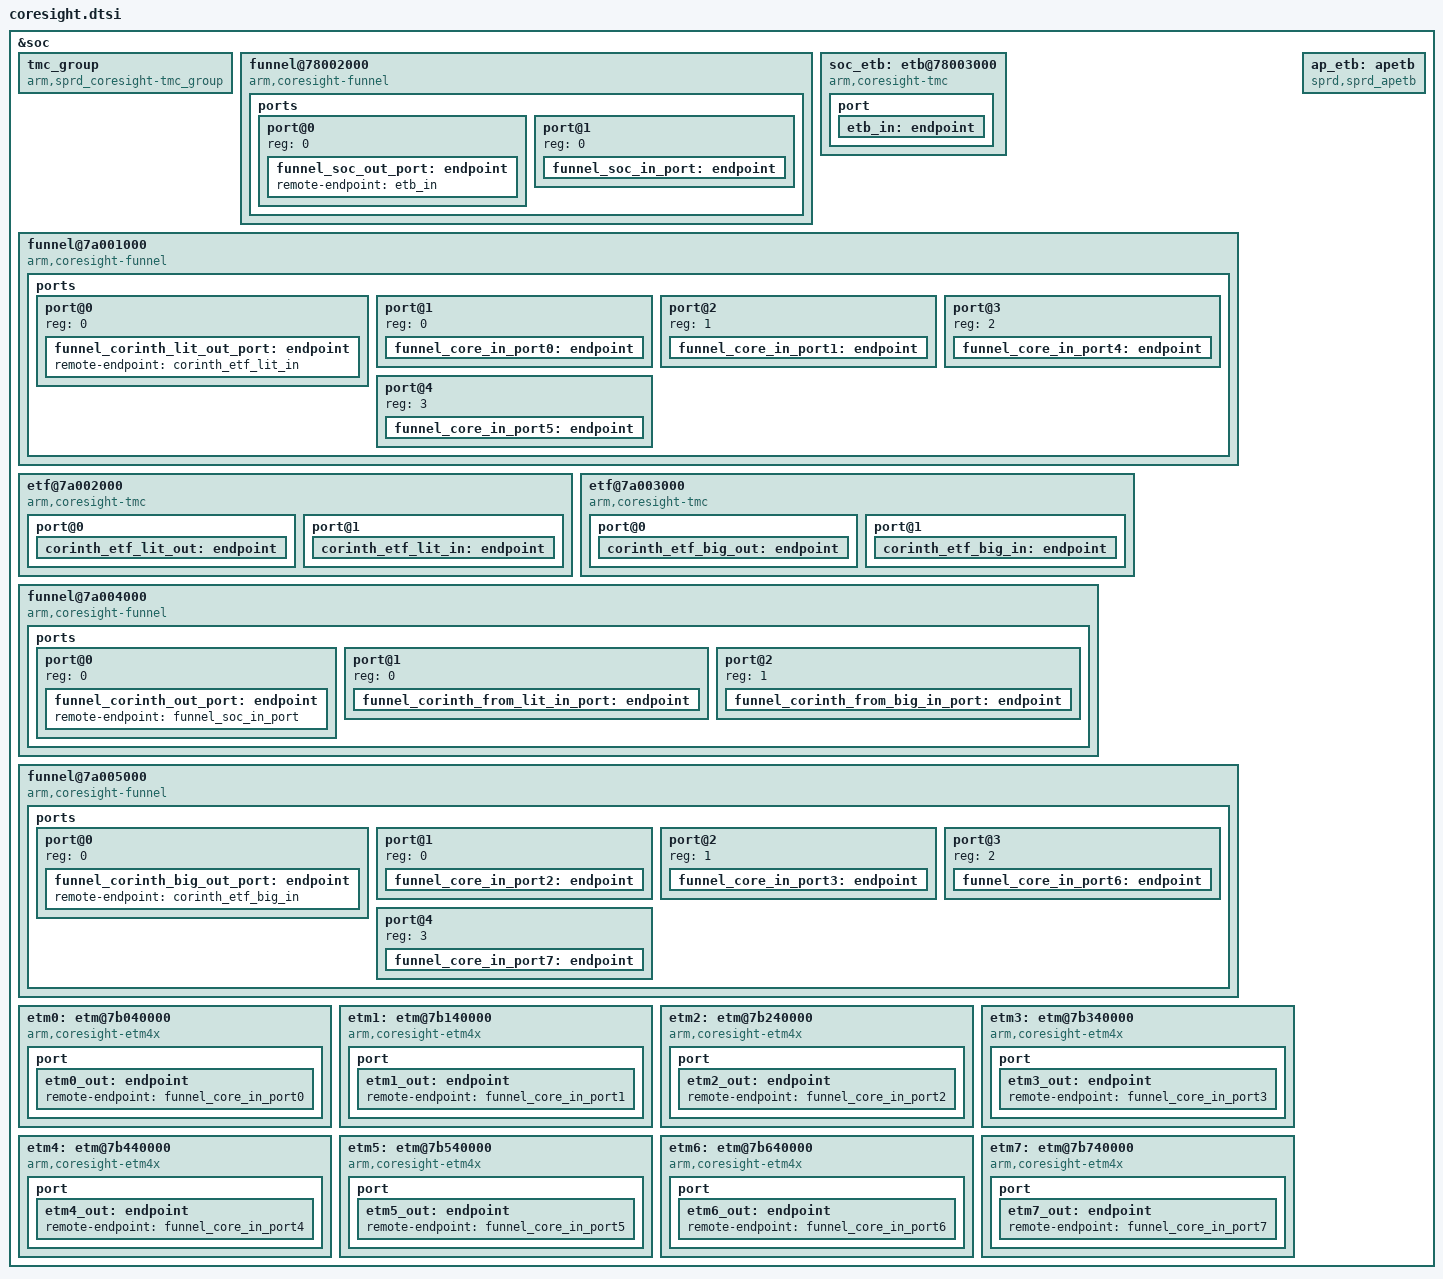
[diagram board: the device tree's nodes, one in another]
// SPDX-License-Identifier: (Licenseref-Unisoc-General-1.0 OR GPL-2.0-only)
/*
 * coresight.dtsi - Unisoc platform device
 *
 * Copyright 2022 Unisoc(Shanghai) Technologies Co.Ltd
 *
 * Licensed under the Unisoc General Software License, version 1.0 (the
 * License);
 * you may not use this file except in compliance with the License.
 * You may obtain a copy of the License at
 * https://www.unisoc.com/en_us/license/UNISOC_GENERAL_LICENSE_V1.0-EN_US
 * Software distributed under the License is distributed on an "AS IS" BASIS,
 * WITHOUT WARRANTIES OF ANY KIND, either express or implied.
 * See the Unisoc General Software License, version 1.0 for more details.
 *
 * Alternatively you can use and distribute this file under the terms of the
 * GNU General Public License version 2, provided that it has to be used
 *  (including but not limited to combining, linking) with any other file under
 * the GNU General Public License version 2 on platforms that use Unisoc Chips.
 */

&soc {
		/*    etm
		 * -> apcpu_funnel lit/big
		 * -> apcpu_etf lit/big
		 * -> funnel_to_soc
		 * -> soc_funnel
		 * -> soc_etf
		 */

		tmc_group {
			compatible = "arm,sprd_coresight-tmc_group", "arm,sprd_tmc_group";
		};

		/* soc_funnel */
		funnel@78002000 {
			compatible = "arm,coresight-funnel", "arm,primecell";
			reg = <0 0x78002000 0 0x1000>;
			clocks = <&ext_26m>;
			clock-names = "apb_pclk";
			ports {
				#address-cells = <1>;
				#size-cells = <0>;

				port@0 {
					reg = <0>;
					funnel_soc_out_port: endpoint {
						remote-endpoint = <&etb_in>;
					};
				};

				port@1 {
					reg = <0>;
					funnel_soc_in_port: endpoint {
						slave-mode;
						remote-endpoint = <&funnel_corinth_out_port>;
					};
				};
			};
		};

		/* soc_etf */
		soc_etb: etb@78003000 {
			compatible = "arm,coresight-tmc", "arm,primecell";
			reg = <0 0x78003000 0 0x1000>;
			clocks = <&ext_26m>;
			clock-names = "apb_pclk";
			port {
				etb_in: endpoint {
					slave-mode;
					remote-endpoint = <&funnel_soc_out_port>;
				};
			};
		};

		/* apcpu funnel lit core0/1/4/5 */
		funnel@7a001000 {
			compatible = "arm,coresight-funnel", "arm,primecell";
			reg = <0 0x7a001000 0 0x1000>;
			clocks = <&ext_26m>;
			clock-names = "apb_pclk";

			ports {
				#address-cells = <1>;
				#size-cells = <0>;

				port@0 {
					reg = <0>;
					funnel_corinth_lit_out_port: endpoint {
						remote-endpoint = <&corinth_etf_lit_in>;
					};
				};

				port@1 {
					reg = <0>;
					funnel_core_in_port0: endpoint {
						slave-mode;
						remote-endpoint = <&etm0_out>;
					};
				};

				port@2 {
					reg = <1>;
					funnel_core_in_port1: endpoint {
						slave-mode;
						remote-endpoint = <&etm1_out>;
					};
				};

				port@3 {
					reg = <2>;
					funnel_core_in_port4: endpoint {
						slave-mode;
						remote-endpoint = <&etm4_out>;
					};
				};

				port@4 {
					reg = <3>;
					funnel_core_in_port5: endpoint {
						slave-mode;
						remote-endpoint = <&etm5_out>;
					};
				};
			};
		};

		/* apcpu lit etf */
		etf@7a002000 {
			compatible = "arm,coresight-tmc", "arm,primecell";
			reg = <0 0x7a002000 0 0x1000>;
			clocks = <&ext_26m>;
			clock-names = "apb_pclk";

			port@0 {
				corinth_etf_lit_out: endpoint {
					remote-endpoint = <&funnel_corinth_from_lit_in_port>;
				};
			};

			port@1 {
				corinth_etf_lit_in: endpoint {
					slave-mode;
					remote-endpoint = <&funnel_corinth_lit_out_port>;
				};
			};
		};

		/* apcpu big etf */
		etf@7a003000 {
			compatible = "arm,coresight-tmc", "arm,primecell";
			reg = <0 0x7a003000 0 0x1000>;
			clocks = <&ext_26m>;
			clock-names = "apb_pclk";

			port@0 {
				corinth_etf_big_out: endpoint {
					remote-endpoint = <&funnel_corinth_from_big_in_port>;
				};
			};

			port@1 {
				corinth_etf_big_in: endpoint {
					slave-mode;
					remote-endpoint = <&funnel_corinth_big_out_port>;
				};
			};
		};

		/* funnel to Soc */
		funnel@7a004000 {
			compatible = "arm,coresight-funnel", "arm,primecell";
			reg = <0 0x7a004000 0 0x1000>;
			clocks = <&ext_26m>;
			clock-names = "apb_pclk";
			ports {
				#address-cells = <1>;
				#size-cells = <0>;

				port@0 {
					reg = <0>;
					funnel_corinth_out_port: endpoint {
						remote-endpoint = <&funnel_soc_in_port>;
					};
				};

				port@1 {
					reg = <0>;
					funnel_corinth_from_lit_in_port: endpoint {
						slave-mode;
						remote-endpoint = <&corinth_etf_lit_out>;
					};
				};

				port@2 {
					reg = <1>;
					funnel_corinth_from_big_in_port: endpoint {
						slave-mode;
						remote-endpoint = <&corinth_etf_big_out>;
					};
				};
			};
		};

		/* apcpu funnel big core2/3/6/7 */
		funnel@7a005000 {
			compatible = "arm,coresight-funnel", "arm,primecell";
			reg = <0 0x7a005000 0 0x1000>;
			clocks = <&ext_26m>;
			clock-names = "apb_pclk";

			ports {
				#address-cells = <1>;
				#size-cells = <0>;

				port@0 {
					reg = <0>;
					funnel_corinth_big_out_port: endpoint {
						remote-endpoint = <&corinth_etf_big_in>;
					};
				};

				port@1 {
					reg = <0>;
					funnel_core_in_port2: endpoint {
						slave-mode;
						remote-endpoint = <&etm2_out>;
					};
				};

				port@2 {
					reg = <1>;
					funnel_core_in_port3: endpoint {
						slave-mode;
						remote-endpoint = <&etm3_out>;
					};
				};

				port@3 {
					reg = <2>;
					funnel_core_in_port6: endpoint {
						slave-mode;
						remote-endpoint = <&etm6_out>;
					};
				};

				port@4 {
					reg = <3>;
					funnel_core_in_port7: endpoint {
						slave-mode;
						remote-endpoint = <&etm7_out>;
					};
				};
			};
		};

		etm0: etm@7b040000 {
			compatible = "arm,coresight-etm4x", "arm,primecell";
			reg = <0 0x7b040000 0 0x1000>;
			cpu = <&CPU0>;
			clocks = <&ext_26m>, <&aonapb_clk CLK_CSSYS>, <&g5l_pll CLK_TGPLL_512M>;
			clock-names = "apb_pclk", "clk_cs", "cs_src";

			port {
				etm0_out: endpoint {
					remote-endpoint = <&funnel_core_in_port0>;
				};
			};
		};

		etm1: etm@7b140000 {
			compatible = "arm,coresight-etm4x", "arm,primecell";
			reg = <0 0x7b140000 0 0x1000>;
			cpu = <&CPU1>;
			clocks = <&ext_26m>, <&aonapb_clk CLK_CSSYS>, <&g5l_pll CLK_TGPLL_512M>;
			clock-names = "apb_pclk", "clk_cs", "cs_src";

			port {
				etm1_out: endpoint {
					remote-endpoint = <&funnel_core_in_port1>;
				};
			};
		};

		etm2: etm@7b240000 {
			compatible = "arm,coresight-etm4x", "arm,primecell";
			reg = <0 0x7b240000 0 0x1000>;
			cpu = <&CPU2>;
			clocks = <&ext_26m>, <&aonapb_clk CLK_CSSYS>, <&g5l_pll CLK_TGPLL_512M>;
			clock-names = "apb_pclk", "clk_cs", "cs_src";

			port {
				etm2_out: endpoint {
					remote-endpoint = <&funnel_core_in_port2>;
				};
			};
		};

		etm3: etm@7b340000 {
			compatible = "arm,coresight-etm4x", "arm,primecell";
			reg = <0 0x7b340000 0 0x1000>;
			cpu = <&CPU3>;
			clocks = <&ext_26m>, <&aonapb_clk CLK_CSSYS>, <&g5l_pll CLK_TGPLL_512M>;
			clock-names = "apb_pclk", "clk_cs", "cs_src";

			port {
				etm3_out: endpoint {
					remote-endpoint = <&funnel_core_in_port3>;
				};
			};
		};

		etm4: etm@7b440000 {
			compatible = "arm,coresight-etm4x", "arm,primecell";
			reg = <0 0x7b440000 0 0x1000>;
			cpu = <&CPU4>;
			clocks = <&ext_26m>, <&aonapb_clk CLK_CSSYS>, <&g5l_pll CLK_TGPLL_512M>;
			clock-names = "apb_pclk", "clk_cs", "cs_src";

			port {
				etm4_out: endpoint {
					remote-endpoint = <&funnel_core_in_port4>;
				};
			};
		};

		etm5: etm@7b540000 {
			compatible = "arm,coresight-etm4x", "arm,primecell";
			reg = <0 0x7b540000 0 0x1000>;
			cpu = <&CPU5>;
			clocks = <&ext_26m>, <&aonapb_clk CLK_CSSYS>, <&g5l_pll CLK_TGPLL_512M>;
			clock-names = "apb_pclk", "clk_cs", "cs_src";

			port {
				etm5_out: endpoint {
					remote-endpoint = <&funnel_core_in_port5>;
				};
			};
		};

		etm6: etm@7b640000 {
			compatible = "arm,coresight-etm4x", "arm,primecell";
			reg = <0 0x7b640000 0 0x1000>;
			cpu = <&CPU6>;
			clocks = <&ext_26m>, <&aonapb_clk CLK_CSSYS>, <&g5l_pll CLK_TGPLL_512M>;
			clock-names = "apb_pclk", "clk_cs", "cs_src";

			port {
				etm6_out: endpoint {
					remote-endpoint = <&funnel_core_in_port6>;
				};
			};
		};

		etm7: etm@7b740000 {
			compatible = "arm,coresight-etm4x", "arm,primecell";
			reg = <0 0x7b740000 0 0x1000>;
			cpu = <&CPU7>;
			clocks = <&ext_26m>, <&aonapb_clk CLK_CSSYS>, <&g5l_pll CLK_TGPLL_512M>;
			clock-names = "apb_pclk", "clk_cs", "cs_src";

			port {
				etm7_out: endpoint {
					remote-endpoint = <&funnel_core_in_port7>;
				};
			};
		};

		ap_etb: apetb {
			compatible = "sprd,sprd_apetb";
			apetb-source = <&etm0 &etm1 &etm2 &etm3 &etm4 &etm5 &etm6 &etm7>;
			apetb-sink = <&soc_etb>;
		};
	};
